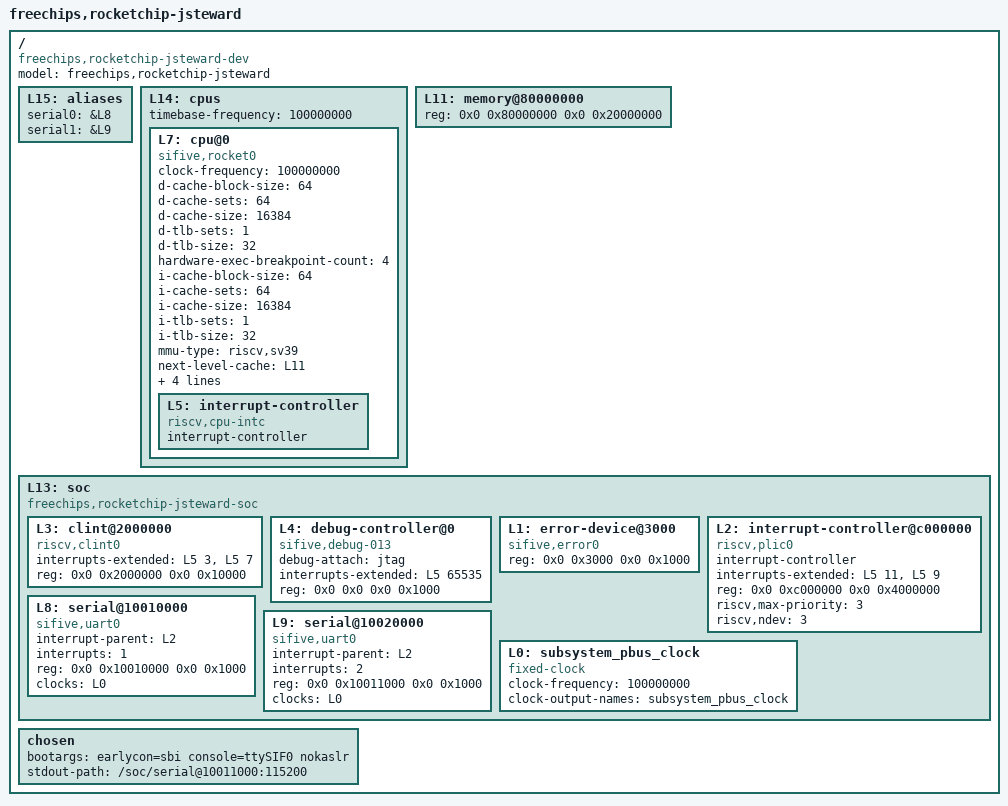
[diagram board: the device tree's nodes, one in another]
/dts-v1/;

/ {
	#address-cells = <2>;
	#size-cells = <2>;
	compatible = "freechips,rocketchip-jsteward-dev";
	model = "freechips,rocketchip-jsteward";
	L15: aliases {
		serial0 = &L8;
		serial1 = &L9;
	};
	L14: cpus {
		#address-cells = <1>;
		#size-cells = <0>;
		timebase-frequency = <100000000>;
		L7: cpu@0 {
			clock-frequency = <100000000>;
			compatible = "sifive,rocket0", "riscv";
			d-cache-block-size = <64>;
			d-cache-sets = <64>;
			d-cache-size = <16384>;
			d-tlb-sets = <1>;
			d-tlb-size = <32>;
			device_type = "cpu";
			hardware-exec-breakpoint-count = <4>;
			i-cache-block-size = <64>;
			i-cache-sets = <64>;
			i-cache-size = <16384>;
			i-tlb-sets = <1>;
			i-tlb-size = <32>;
			mmu-type = "riscv,sv39";
			next-level-cache = <&L11>;
			reg = <0x0>;
			riscv,isa = "rv64imafdc";
			riscv,pmpregions = <8>;
			status = "okay";
			tlb-split;
			L5: interrupt-controller {
				#interrupt-cells = <1>;
				compatible = "riscv,cpu-intc";
				interrupt-controller;
			};
		};
	};
	L11: memory@80000000 {
		device_type = "memory";
		reg = <0x0 0x80000000 0x0 0x20000000>;
	};
    /*
	reserved-memory {
		#address-cells = <2>;
		#size-cells = <2>;
		ranges;
		DLA: reserved@870000000 {
			no-map;
			reg = <0x8 0x70000000 0x0 0x10000000>;
		};
	};
    */
	L13: soc {
		#address-cells = <2>;
		#size-cells = <2>;
		compatible = "freechips,rocketchip-jsteward-soc", "simple-bus";
		ranges;
		L3: clint@2000000 {
			compatible = "riscv,clint0";
			interrupts-extended = <&L5 3 &L5 7>;
			reg = <0x0 0x2000000 0x0 0x10000>;
			reg-names = "control";
		};
		L4: debug-controller@0 {
			compatible = "sifive,debug-013", "riscv,debug-013";
			debug-attach = "jtag";
			interrupts-extended = <&L5 65535>;
			reg = <0x0 0x0 0x0 0x1000>;
			reg-names = "control";
		};
		L1: error-device@3000 {
			compatible = "sifive,error0";
			reg = <0x0 0x3000 0x0 0x1000>;
		};
		L2: interrupt-controller@c000000 {
			#interrupt-cells = <1>;
			compatible = "riscv,plic0";
			interrupt-controller;
			interrupts-extended = <&L5 11 &L5 9>;
			reg = <0x0 0xc000000 0x0 0x4000000>;
			reg-names = "control";
			riscv,max-priority = <3>;
			riscv,ndev = <3>;
		};
        /*
		L10: nvdla@10040000 {
			compatible = "nvidia,nv_small";
			interrupt-parent = <&L2>;
			interrupts = <3>;
			reg = <0x0 0x10040000 0x0 0x40000>;
			reg-names = "control";
			memory-region = <&DLA>;
		};
        */
		L8: serial@10010000 {
			compatible = "sifive,uart0";
			interrupt-parent = <&L2>;
			interrupts = <1>;
			reg = <0x0 0x10010000 0x0 0x1000>;
			reg-names = "control";
			clocks = <&L0>;
		};
		L9: serial@10020000 {
			compatible = "sifive,uart0";
			interrupt-parent = <&L2>;
			interrupts = <2>;
			reg = <0x0 0x10011000 0x0 0x1000>;
			reg-names = "control";
			clocks = <&L0>;
		};
		L0: subsystem_pbus_clock {
			#clock-cells = <0>;
			clock-frequency = <100000000>;
			clock-output-names = "subsystem_pbus_clock";
			compatible = "fixed-clock";
		};
	};

	chosen {
		bootargs = "earlycon=sbi console=ttySIF0 nokaslr";
		stdout-path = "/soc/serial@10011000:115200";
	};
};
